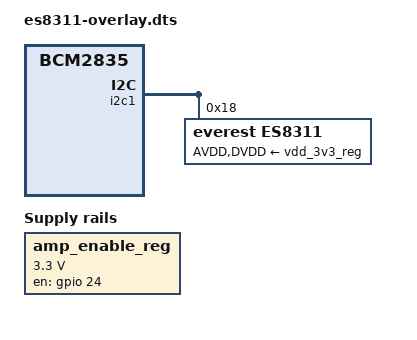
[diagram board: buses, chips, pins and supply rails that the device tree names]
// Definitions for ES8311 audio codec
/dts-v1/;
/plugin/;

#include <dt-bindings/gpio/gpio.h>

/ {
	compatible = "brcm,bcm2835";

	fragment@0 {
		target = <&i2s_clk_producer>;
		__overlay__ {
			status = "okay";
		};
	};

	fragment@1 {
		target-path = "/";
		__overlay__ {
			amp_enable_reg: amp_enable_regulator {
				compatible = "regulator-fixed";
				regulator-name = "amp-enable";
				regulator-min-microvolt = <3300000>;
				regulator-max-microvolt = <3300000>;
				gpio = <&gpio 24 0>; /* GPIO24, active high */
				enable-active-high;
				regulator-always-on;
			};
		};
	};

	fragment@2 {
		target = <&i2c1>;
		__overlay__ {
			#address-cells = <1>;
			#size-cells = <0>;
			status = "okay";

			es8311: es8311@18 {
				compatible = "everest,es8311";
				reg = <0x18>;
				#sound-dai-cells = <0>;
				AVDD-supply = <&vdd_3v3_reg>;
				DVDD-supply = <&vdd_3v3_reg>;
			};
		};
	};

	fragment@3 {
		target = <&sound>;
		slave_overlay: __overlay__ {
			compatible = "simple-audio-card";
			simple-audio-card,format = "i2s";
			simple-audio-card,name = "es8311-soundcard";
			status = "okay";

			simple-audio-card,widgets =
				"Microphone", "Internal Mic",
				"Speaker", "Internal Speaker";
			simple-audio-card,routing =
				"Internal Speaker", "OUT",
				"MIC1", "Internal Mic";

			simple-audio-card,aux-devs = <&amp_enable_reg>;

			simple-audio-card,cpu {
				sound-dai = <&i2s_clk_producer>;
			};

			dailink0_slave: simple-audio-card,codec {
				sound-dai = <&es8311>;
			};
		};
	};

	__overrides__ {
		alsaname = <&slave_overlay>,"simple-audio-card,name";
		compatible = <&es8311>,"compatible";
		amp_gpio = <&amp_enable_reg>,"gpio:4";
	};
};
